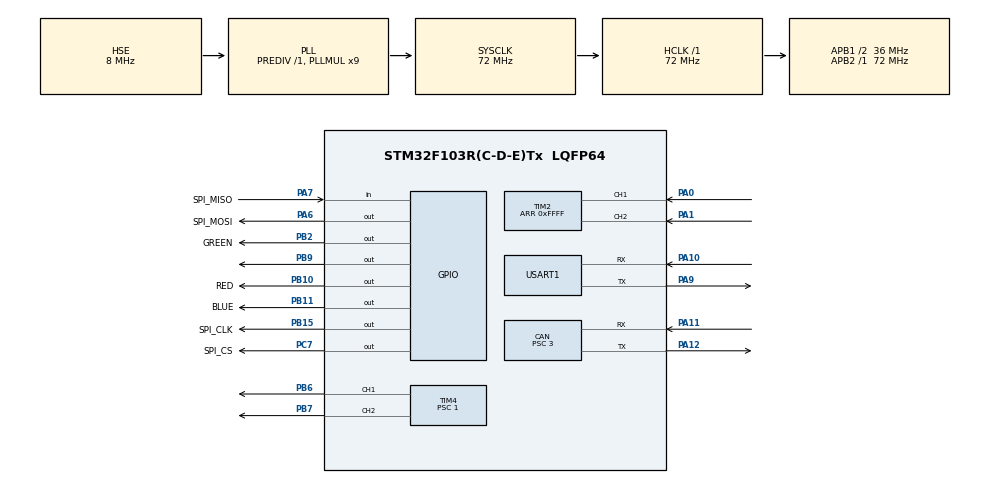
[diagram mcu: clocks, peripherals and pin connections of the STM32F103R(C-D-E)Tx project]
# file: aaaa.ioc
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CAN.ABOM=ENABLE
CAN.BS1=CAN_BS1_9TQ
CAN.BS2=CAN_BS2_2TQ
CAN.CalculateTimeBit=1000
CAN.CalculateTimeQuantum=83.33333333333334
CAN.Prescaler=3
CAN.TXFP=ENABLE
Dma.Request0=USART1_TX
Dma.USART1_TX.0.Direction=DMA_MEMORY_TO_PERIPH
Dma.USART1_TX.0.Instance=DMA1_Channel4
Dma.USART1_TX.0.MemDataAlignment=DMA_MDATAALIGN_BYTE
Dma.USART1_TX.0.MemInc=DMA_MINC_ENABLE
Dma.USART1_TX.0.Mode=DMA_NORMAL
Dma.USART1_TX.0.PeriphDataAlignment=DMA_PDATAALIGN_BYTE
Dma.USART1_TX.0.PeriphInc=DMA_PINC_DISABLE
Dma.USART1_TX.0.Priority=DMA_PRIORITY_HIGH
Mcu.Family=STM32F1
Mcu.Name=STM32F103R(C-D-E)Tx
Mcu.Package=LQFP64
NVIC.DMA1_Channel4_IRQn=true\:0\:0\:false\:false\:true\:false
NVIC.PriorityGroup=NVIC_PRIORITYGROUP_4
NVIC.USART1_IRQn=true\:1\:0\:true\:true\:true\:1\:true
NVIC.USB_LP_CAN1_RX0_IRQn=true\:0\:0\:false\:true\:true\:2\:true
PA0-WKUP.Signal=S_TIM2_CH1_ETR
PA1.Signal=S_TIM2_CH2
PA10.Mode=Asynchronous
PA10.Signal=USART1_RX
PA11.Mode=Master
PA11.Signal=CAN_RX
PA12.Mode=Master
PA12.Signal=CAN_TX
PA13.Mode=Serial_Wire
PA13.Signal=SYS_JTMS-SWDIO
PA14.Mode=Serial_Wire
PA14.Signal=SYS_JTCK-SWCLK
PA6.GPIO_Label=SPI_MOSI
PA6.Signal=GPIO_Output
PA7.GPIO_Label=SPI_MISO
PA7.Signal=GPIO_Input
PA9.Mode=Asynchronous
PA9.Signal=USART1_TX
PB10.GPIO_Label=RED
PB10.Signal=GPIO_Output
PB11.GPIO_Label=BLUE
PB11.Signal=GPIO_Output
PB15.GPIO_Label=SPI_CLK
PB15.Signal=GPIO_Output
PB2.GPIO_Label=GREEN
PB2.Signal=GPIO_Output
PB6.Signal=S_TIM4_CH1
PB7.Signal=S_TIM4_CH2
PB9.Signal=GPIO_Output
PC7.GPIO_Label=SPI_CS
PC7.Signal=GPIO_Output
PD0-OSC_IN.Mode=HSE-External-Oscillator
PD0-OSC_IN.Signal=RCC_OSC_IN
PD1-OSC_OUT.Mode=HSE-External-Oscillator
PD1-OSC_OUT.Signal=RCC_OSC_OUT
ProjectManager.HeapSize=0x200
ProjectManager.StackSize=0x400
ProjectManager.TargetToolchain=EWARM V7
RCC.AHBFreq_Value=72000000
RCC.APB1CLKDivider=RCC_HCLK_DIV2
RCC.APB1Freq_Value=36000000
RCC.APB1TimFreq_Value=72000000
RCC.APB2Freq_Value=72000000
RCC.APB2TimFreq_Value=72000000
RCC.HCLKFreq_Value=72000000
RCC.PLLMUL=RCC_PLL_MUL9
RCC.PLLSourceVirtual=RCC_PLLSOURCE_HSE
RCC.SYSCLKFreq_VALUE=72000000
RCC.SYSCLKSource=RCC_SYSCLKSOURCE_PLLCLK
RCC.USBFreq_Value=72000000
SH.S_TIM2_CH1_ETR.0=TIM2_CH1,Encoder_Interface
SH.S_TIM2_CH2.0=TIM2_CH2,Encoder_Interface
SH.S_TIM4_CH1.0=TIM4_CH1,PWM Generation1 CH1
SH.S_TIM4_CH2.0=TIM4_CH2,PWM Generation2 CH2
TIM2.EncoderMode=TIM_ENCODERMODE_TI12
TIM2.Period=0xFFFF
TIM4.Channel-PWM\ Generation1\ CH1=TIM_CHANNEL_1
TIM4.Channel-PWM\ Generation2\ CH2=TIM_CHANNEL_2
TIM4.OCMode_PWM-PWM\ Generation1\ CH1=TIM_OCMODE_PWM1
TIM4.OCPolarity_1=TIM_OCPOLARITY_LOW
TIM4.OCPolarity_2=TIM_OCPOLARITY_LOW
TIM4.Period=3000
TIM4.Prescaler=1
TIM6.Period=0xFFFF
TIM6.Prescaler=71
USART1.VirtualMode=VM_ASYNC
VP_TIM6_VS_ClockSourceINT.Mode=Enable_Timer
VP_TIM7_VS_ClockSourceINT.Mode=Enable_Timer
board=custom

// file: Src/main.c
/**
  ******************************************************************************
  * @file           : main.c
  * @brief          : Main program body
  ******************************************************************************
  ** This notice applies to any and all portions of this file
  * that are not between comment pairs USER CODE BEGIN and
  * USER CODE END. Other portions of this file, whether
  * inserted by the user or by software development tools
  * are owned by their respective copyright owners.
  *
  * COPYRIGHT(c) 2018 STMicroelectronics
  *
  * Redistribution and use in source and binary forms, with or without modification,
  * are permitted provided that the following conditions are met:
  *   1. Redistributions of source code must retain the above copyright notice,
  *      this list of conditions and the following disclaimer.
  *   2. Redistributions in binary form must reproduce the above copyright notice,
  *      this list of conditions and the following disclaimer in the documentation
  *      and/or other materials provided with the distribution.
  *   3. Neither the name of STMicroelectronics nor the names of its contributors
  *      may be used to endorse or promote products derived from this software
  *      without specific prior written permission.
  *
  * THIS SOFTWARE IS PROVIDED BY THE COPYRIGHT HOLDERS AND CONTRIBUTORS "AS IS"
  * AND ANY EXPRESS OR IMPLIED WARRANTIES, INCLUDING, BUT NOT LIMITED TO, THE
  * IMPLIED WARRANTIES OF MERCHANTABILITY AND FITNESS FOR A PARTICULAR PURPOSE ARE
  * DISCLAIMED. IN NO EVENT SHALL THE COPYRIGHT HOLDER OR CONTRIBUTORS BE LIABLE
  * FOR ANY DIRECT, INDIRECT, INCIDENTAL, SPECIAL, EXEMPLARY, OR CONSEQUENTIAL
  * DAMAGES (INCLUDING, BUT NOT LIMITED TO, PROCUREMENT OF SUBSTITUTE GOODS OR
  * SERVICES; LOSS OF USE, DATA, OR PROFITS; OR BUSINESS INTERRUPTION) HOWEVER
  * CAUSED AND ON ANY THEORY OF LIABILITY, WHETHER IN CONTRACT, STRICT LIABILITY,
  * OR TORT (INCLUDING NEGLIGENCE OR OTHERWISE) ARISING IN ANY WAY OUT OF THE USE
  * OF THIS SOFTWARE, EVEN IF ADVISED OF THE POSSIBILITY OF SUCH DAMAGE.
  *
  ******************************************************************************
  */
#include "main.h"
#include "stm32f1xx_hal.h"
#include "can.h"
#include "dma.h"
#include "tim.h"
#include "usart.h"
#include "gpio.h"

/* USER CODE BEGIN Includes */
#include "control.h"
#include "command.h"
/* USER CODE END Includes */

/* USER CODE BEGIN PV */
/* Private variables ---------------------------------------------------------*/
uint8_t Time_5ms_Flag=0;
uint8_t Init_OK_Flag=0;
/* USER CODE END PV */

void SystemClock_Config(void);
static void MX_NVIC_Init(void);

/* USER CODE BEGIN PFP */
/* Private function prototypes -----------------------------------------------*/

/* USER CODE END PFP */

int main(void)
{

  /* MCU Configuration----------------------------------------------------------*/

  /* Reset of all peripherals, Initializes the Flash interface and the Systick. */
  HAL_Init();

  /* Configure the system clock */
  SystemClock_Config();

  /* Initialize all configured peripherals */
  MX_GPIO_Init();
  MX_DMA_Init();
  MX_USART1_UART_Init();
  MX_TIM4_Init();
  MX_TIM2_Init();
  MX_CAN_Init();
  MX_TIM6_Init();
  MX_TIM7_Init();

  /* Initialize interrupts */
  MX_NVIC_Init();
  command_init();
  /* USER CODE BEGIN 2 */
  Init_OK_Flag=1;
  /* USER CODE END 2 */

  /* Infinite loop */
  while (1)
  {
    if(buffer_rx_OK){
      analize(buffer_rx);
      buffer_rx_OK=0;
    }
    if(Time_5ms_Flag){
      Get_Speed();
      Control();
      Time_5ms_Flag=0;
    }
  }

}

void SystemClock_Config(void)
{

  RCC_OscInitTypeDef RCC_OscInitStruct;
  RCC_ClkInitTypeDef RCC_ClkInitStruct;

    /**Initializes the CPU, AHB and APB busses clocks
    */
  RCC_OscInitStruct.OscillatorType = RCC_OSCILLATORTYPE_HSE;
  RCC_OscInitStruct.HSEState = RCC_HSE_ON;
  RCC_OscInitStruct.HSEPredivValue = RCC_HSE_PREDIV_DIV1;
  RCC_OscInitStruct.HSIState = RCC_HSI_ON;
  RCC_OscInitStruct.PLL.PLLState = RCC_PLL_ON;
  RCC_OscInitStruct.PLL.PLLSource = RCC_PLLSOURCE_HSE;
  RCC_OscInitStruct.PLL.PLLMUL = RCC_PLL_MUL9;
  if (HAL_RCC_OscConfig(&RCC_OscInitStruct) != HAL_OK)
  {
    _Error_Handler(__FILE__, __LINE__);
  }

    /**Initializes the CPU, AHB and APB busses clocks
    */
  RCC_ClkInitStruct.ClockType = RCC_CLOCKTYPE_HCLK|RCC_CLOCKTYPE_SYSCLK
                              |RCC_CLOCKTYPE_PCLK1|RCC_CLOCKTYPE_PCLK2;
  RCC_ClkInitStruct.SYSCLKSource = RCC_SYSCLKSOURCE_PLLCLK;
  RCC_ClkInitStruct.AHBCLKDivider = RCC_SYSCLK_DIV1;
  RCC_ClkInitStruct.APB1CLKDivider = RCC_HCLK_DIV2;
  RCC_ClkInitStruct.APB2CLKDivider = RCC_HCLK_DIV1;

  if (HAL_RCC_ClockConfig(&RCC_ClkInitStruct, FLASH_LATENCY_2) != HAL_OK)
  {
    _Error_Handler(__FILE__, __LINE__);
  }

    /**Configure the Systick interrupt time
    */
  HAL_SYSTICK_Config(HAL_RCC_GetHCLKFreq()/1000);

    /**Configure the Systick
    */
  HAL_SYSTICK_CLKSourceConfig(SYSTICK_CLKSOURCE_HCLK);

  /* SysTick_IRQn interrupt configuration */
  HAL_NVIC_SetPriority(SysTick_IRQn, 0, 0);
}

/**
  * @brief NVIC Configuration.
  * @retval None
  */
static void MX_NVIC_Init(void)
{
  /* USART1_IRQn interrupt configuration */
  HAL_NVIC_SetPriority(USART1_IRQn, 1, 0);
  HAL_NVIC_EnableIRQ(USART1_IRQn);
  /* USB_LP_CAN1_RX0_IRQn interrupt configuration */
  HAL_NVIC_SetPriority(USB_LP_CAN1_RX0_IRQn, 0, 0);
  HAL_NVIC_EnableIRQ(USB_LP_CAN1_RX0_IRQn);
}

/* USER CODE BEGIN 4 */
void HAL_SYSTICK_Callback(void){
  static int time_1ms_cnt;
  if(!Init_OK_Flag){
    return ;
  }
  time_1ms_cnt++;
  if(time_1ms_cnt%5==0){
    Time_5ms_Flag=1;
  }

  if(time_1ms_cnt%2==0){
    send_wave(Now_Speed,Now_Position,0,0);
  }
}
/* USER CODE END 4 */

void _Error_Handler(char *file, int line)
{
  while(1)
  {
  }
}

/************************ (C) COPYRIGHT STMicroelectronics *****END OF FILE****/
